# MKW31Z4 register map
Vendor: Freescale Semiconductor, Inc.; Series: Kinetis_W; File version: 1.6
CPU: CM0PLUS r0p0, little endian, no MPU, no FPU, VTOR, 2 interrupt priority bits
Registers are 16-bit, read-write, no defined reset value unless marked. A register's access mark holds for its fields unless they carry their own. Offsets are from the block's base; [hi:lo] are bit positions; {n}, {i} and the like mark numbered series.

## ANT_REGS — ANT
Base 0x4005E000
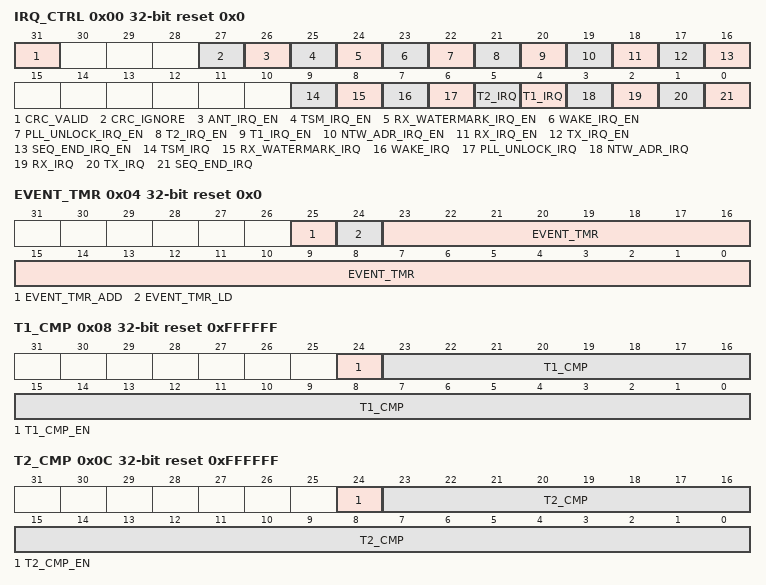
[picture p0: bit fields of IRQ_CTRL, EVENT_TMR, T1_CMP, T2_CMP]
0x00 IRQ_CTRL 32-bit reset 0x0 (reset mask 0x7FFFFC00) — IRQ CONTROL
  [31] CRC_VALID ro
    0=CRC of RX packet is not valid; 1=CRC of RX packet is valid
  [27] CRC_IGNORE
    0=RX_IRQ will not be asserted for a received packet which fails CRC verification; 1=RX_IRQ will be asserted even for a received packet which fails CRC verification
  [26] ANT_IRQ_EN — ANT_IRQ Master Enable
    0=All ANT Interrupts are disabled; 1=All ANT Interrupts can be enabled
  [25] TSM_IRQ_EN — TSM_IRQ Enable
    0=TSM Interrupt is not enabled; 1=TSM Interrupt is enabled
  [24] RX_WATERMARK_IRQ_EN — RX_WATERMARK_IRQ Enable
    0=RX Watermark Interrupt is not enabled; 1=RX Watermark Interrupt is enabled
  [23] WAKE_IRQ_EN — WAKE_IRQ Enable
    0=Wake Interrupt is not enabled; 1=Wake Interrupt is enabled
  [22] PLL_UNLOCK_IRQ_EN — PLL_UNLOCK_IRQ Enable
    0=PLL Unlock Interrupt is not enabled; 1=PLL Unlock Interrupt is enabled
  [21] T2_IRQ_EN — T2_IRQ Enable
    0=Timer1 (T2) Compare Interrupt is not enabled; 1=Timer1 (T2) Compare Interrupt is enabled
  [20] T1_IRQ_EN — T1_IRQ Enable
    0=Timer1 (T1) Compare Interrupt is not enabled; 1=Timer1 (T1) Compare Interrupt is enabled
  [19] NTW_ADR_IRQ_EN — NTW_ADR_IRQ Enable
    0=Network Address Match Interrupt is not enabled; 1=Network Address Match Interrupt is enabled
  [18] RX_IRQ_EN — RX_IRQ Enable
    0=RX Interrupt is not enabled; 1=RX Interrupt is enabled
  [17] TX_IRQ_EN — TX_IRQ Enable
    0=TX Interrupt is not enabled; 1=TX Interrupt is enabled
  [16] SEQ_END_IRQ_EN — SEQ_END_IRQ Enable
    0=Sequence End Interrupt is not enabled; 1=Sequence End Interrupt is enabled
  [9] TSM_IRQ ro — TSM Interrupt
    0=TSM0_IRQ and TSM1_IRQ are both clear; 1=Indicates TSM0_IRQ or TSM1_IRQ is set in XCVR_STATUS
  [8] RX_WATERMARK_IRQ — RX Watermark Interrupt
    0=RX Watermark Interrupt is not asserted; 1=RX Watermark Interrupt is asserted
  [7] WAKE_IRQ — Wake Interrrupt
    0=Wake Interrupt is not asserted; 1=Wake Interrupt is asserted
  [6] PLL_UNLOCK_IRQ — PLL Unlock Interrupt
    0=PLL Unlock Interrupt is not asserted; 1=PLL Unlock Interrupt is asserted
  [5] T2_IRQ — Timer2 (T2) Compare Interrupt
    0=Timer2 (T2) Compare Interrupt is not asserted; 1=Timer2 (T2) Compare Interrupt is asserted
  [4] T1_IRQ — Timer1 (T1) Compare Interrupt
    0=Timer1 (T1) Compare Interrupt is not asserted; 1=Timer1 (T1) Compare Interrupt is asserted
  [3] NTW_ADR_IRQ — Network Address Match Interrupt
    0=Network Address Match Interrupt is not asserted; 1=Network Address Match Interrupt is asserted
  [2] RX_IRQ — RX Interrupt
    0=RX Interrupt is not asserted; 1=RX Interrupt is asserted
  [1] TX_IRQ — TX Interrupt
    0=TX Interrupt is not asserted; 1=TX Interrupt is asserted
  [0] SEQ_END_IRQ — Sequence End Interrupt
    0=Sequence End Interrupt is not asserted; 1=Sequence End Interrupt is asserted
0x04 EVENT_TMR 32-bit reset 0x0 (reset mask 0xFF000000) — EVENT TIMER
  [25] EVENT_TMR_ADD wo — Event Timer Add
  [24] EVENT_TMR_LD wo — Event Timer Load
  [23:0] EVENT_TMR — Event Timer
0x08 T1_CMP 32-bit reset 0xFFFFFF — T1 COMPARE
  [24] T1_CMP_EN — Timer1 (T1) Compare Enable
  [23:0] T1_CMP — Timer1 (T1) Compare Value
0x0C T2_CMP 32-bit reset 0xFFFFFF — T2 COMPARE
  [24] T2_CMP_EN — Timer2 (T2) Compare Enable
  [23:0] T2_CMP — Timer2 (T2) Compare Value
0x10 TIMESTAMP 32-bit ro reset 0x0 (reset mask 0xFF000000)
  [23:0] TIMESTAMP — Received Packet Timestamp
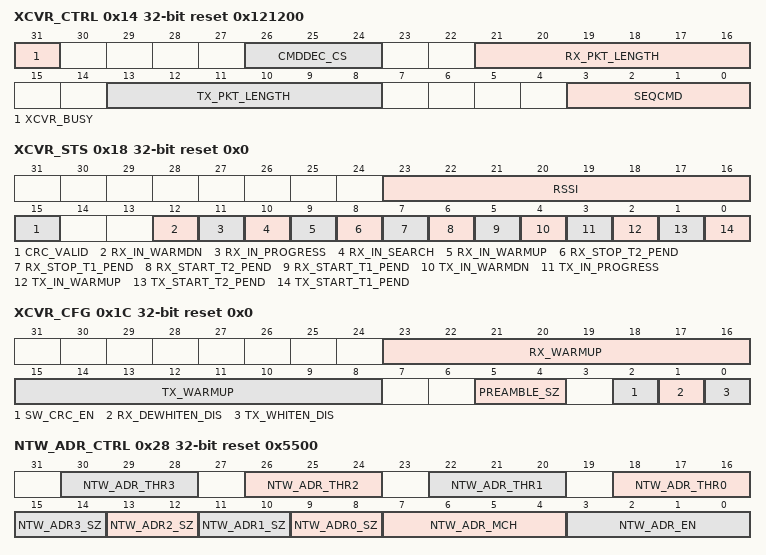
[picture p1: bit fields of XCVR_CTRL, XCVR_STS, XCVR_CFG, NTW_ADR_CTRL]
0x14 XCVR_CTRL 32-bit reset 0x121200 (reset mask 0x78FFFFFF) — TRANSCEIVER CONTROL
  [31] XCVR_BUSY ro — Transceiver Busy
    0=IDLE; 1=BUSY
  [26:24] CMDDEC_CS ro — Command Decode
  [21:16] RX_PKT_LENGTH — Receive Packet Length
  [13:8] TX_PKT_LENGTH — Transmit Packet Length
  [3:0] SEQCMD — Sequence Commands
    0=No Action; 1=TX Start Now; 2=TX Start @ T1 Timer Compare Match (EVENT_TMR = T1_CMP); 3=TX Start @ T2 Timer Compare Match (EVENT_TMR = T2_CMP); 4=TX Cancel -- Cancels pending TX events but do not abort a TX-in-progress; 5=RX Start Now; 6=RX Start @ T1 Timer Compare Match (EVENT_TMR = T1_CMP); 7=RX Start @ T2 Timer Compare Match (EVENT_TMR = T2_CMP); 8=RX Stop @ T1 Timer Compare Match (EVENT_TMR = T1_CMP); 9=RX Stop @ T2 Timer Compare Match (EVENT_TMR = T2_CMP); 10=RX Cancel -- Cancels pending RX events but do not abort a RX-in-progress; 11=Abort All - Cancels all pending events and abort any sequence-in-progress
0x18 XCVR_STS 32-bit ro reset 0x0 (reset mask 0xFF006000) — TRANSCEIVER STATUS
  [23:16] RSSI — Received Signal Stength Indicator
  [15] CRC_VALID — CRC Valid Indicator
    0=CRC is not valid for RX packet; 1=CRC is valid for RX packet
  [12] RX_IN_WARMDN — RX Warmdown Status
  [11] RX_IN_PROGRESS — RX in Progress Status
  [10] RX_IN_SEARCH — RX Search Status
  [9] RX_IN_WARMUP — RX Warmup Status
  [8] RX_STOP_T2_PEND — RX T2 Start Pending Status
  [7] RX_STOP_T1_PEND — RX T1 Stop Pending Status
  [6] RX_START_T2_PEND — RX T2 Start Pending Status
  [5] RX_START_T1_PEND — RX T1 Start Pending Status
  [4] TX_IN_WARMDN — TX Warmdown Status
  [3] TX_IN_PROGRESS — TX in Progress Status
  [2] TX_IN_WARMUP — TX Warmup Status
  [1] TX_START_T2_PEND — TX T2 Start Pending Status
  [0] TX_START_T1_PEND — TX T1 Start Pending Status
0x1C XCVR_CFG 32-bit reset 0x0 (reset mask 0xFF0000FF) — TRANSCEIVER CONFIGURATION
  [23:16] RX_WARMUP ro — Receive Warmup Time
  [15:8] TX_WARMUP ro — Transmit Warmup Time
  [5:4] PREAMBLE_SZ — Preamble Size
  [2] SW_CRC_EN — Software CRC Enable
  [1] RX_DEWHITEN_DIS — RX De-Whitening Disable
  [0] TX_WHITEN_DIS — TX Whitening Disable
0x20 CHANNEL_NUM 32-bit reset 0x0 — CHANNEL NUMBER
  [6:0] CHANNEL_NUM — Channel Number
0x24 TX_POWER 32-bit reset 0x0 — TRANSMIT POWER
  [5:0] TX_POWER — Transmit Power
0x28 NTW_ADR_CTRL 32-bit reset 0x5500 (reset mask 0xFFFFFF0F) — NETWORK ADDRESS CONTROL
  [4n+18:4n+16] NTW_ADR_THR{n} (n=0..3) — Network Address Match Bit Error Threshold {n}
  [2n+9:2n+8] NTW_ADR{n}_SZ (n=0..3) — Network Address Match Size
    0=1 octet; 1=2 octets; 2=3 octets; 3=4 octets
  [7:4] NTW_ADR_MCH ro — Network Address Match Status
  [3:0] NTW_ADR_EN — Network Address Match Enable
{0x2C+4i} NTW_ADR_{i} 32-bit reset 0x55555555 (i=0..2) — NETWORK ADDRESS {i}
  [31:0] NTW_ADR_{i} — Network Address {i}
0x38 NTW_ADR_3 32-bit reset 0x55555555 — NETWORK ADDRESS 3
  [31:0] NTW_ADR_3 — Network Address 2
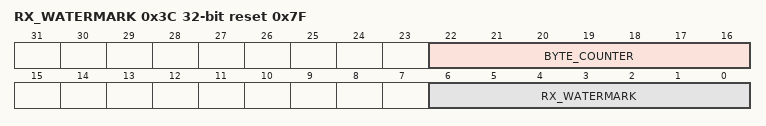
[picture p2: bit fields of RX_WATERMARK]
0x3C RX_WATERMARK 32-bit reset 0x7F (reset mask 0xFF80FFFF)
  [22:16] BYTE_COUNTER ro
    0b1xxxxxx=When less than 0, Preamble byte(s), TX only; 0=First Byte of Network Address; 1=Second Byte of Network Address
  [6:0] RX_WATERMARK
0x40 DSM_CTRL 32-bit reset 0x0 (reset mask 0xFFFFFFFE) — DSM CONTROL
  [0] ANT_SLEEP_EN wo — ANT DSM Sleep Enable
0x44 PART_ID 32-bit ro reset 0x0
  [7:0] PART_ID
{0x100+2i} PACKET_BUFFER_{i} (i=0..63) — PACKET BUFFER
  [15:0] PACKET_BUFFER — PACKET BUFFER RAM
